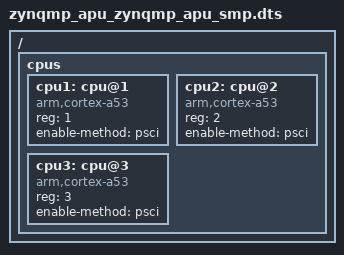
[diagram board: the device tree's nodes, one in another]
/*
 * Copyright (c) 2026 Advanced Micro Devices, Inc.
 *
 * SPDX-License-Identifier: Apache-2.0
 */

/dts-v1/;
#include "zynqmp_apu.dts"

/ {
	cpus {
		cpu1: cpu@1 {
			compatible = "arm,cortex-a53";
			reg = <1>;
			device_type = "cpu";
			enable-method = "psci";
		};

		cpu2: cpu@2 {
			compatible = "arm,cortex-a53";
			reg = <2>;
			device_type = "cpu";
			enable-method = "psci";
		};

		cpu3: cpu@3 {
			compatible = "arm,cortex-a53";
			reg = <3>;
			device_type = "cpu";
			enable-method = "psci";
		};
	};
};
